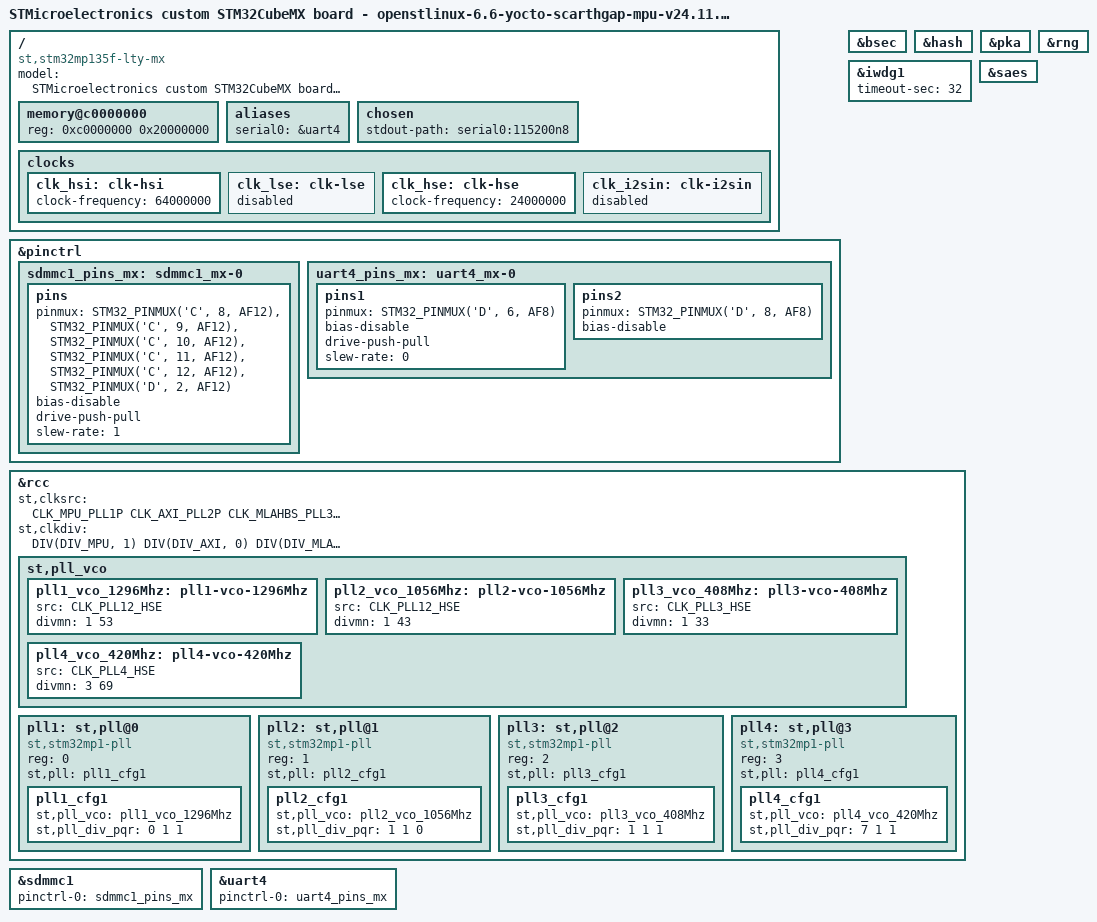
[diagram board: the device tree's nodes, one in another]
// SPDX-License-Identifier: (GPL-2.0-or-later OR BSD-3-Clause)
/*
 * Copyright (C) 2026, STMicroelectronics - All Rights Reserved
 * Author: STM32CubeMX code generation for STMicroelectronics.
 */

/* For more information on Device Tree configuration, please refer to
 * https://wiki.st.com/stm32mpu/wiki/Category:Device_tree_configuration
 */

/dts-v1/;

#include <dt-bindings/pinctrl/stm32-pinfunc.h>
#include <dt-bindings/clock/stm32mp13-clksrc.h>
#include "stm32mp13-mx.dtsi"

#include "stm32mp135.dtsi"
#include "stm32mp13xf.dtsi"
#include "stm32mp13-ddr.dtsi"

/* USER CODE BEGIN includes */
#include "stm32mp13-pinctrl.dtsi"
/* USER CODE END includes */

/ {
	model = "STMicroelectronics custom STM32CubeMX board - openstlinux-6.6-yocto-scarthgap-mpu-v24.11.06";
	compatible = "st,stm32mp135f-lty-mx", "st,stm32mp135";

	memory@c0000000 {
		device_type = "memory";
		reg = <0xc0000000 0x20000000>;

		/* USER CODE BEGIN memory */
		/* USER CODE END memory */
	};

	/* USER CODE BEGIN root */

	aliases {
		serial0 = &uart4;
	};

	chosen {
		stdout-path = "serial0:115200n8";
	}; 
	
    chosen {
        stdout-path = "serial0:115200n8";
    };	
    
  	/* USER CODE END root */

	clocks {
		/* USER CODE BEGIN clocks */
		/* USER CODE END clocks */

		clk_hsi: clk-hsi {
			clock-frequency = <64000000>;

			/* USER CODE BEGIN clk_hsi */
			/* USER CODE END clk_hsi */
		};
		clk_lse: clk-lse {
			status = "disabled";

			/* USER CODE BEGIN clk_lse */
			/* USER CODE END clk_lse */
		};
		clk_hse: clk-hse {
			clock-frequency = <24000000>;

			/* USER CODE BEGIN clk_hse */
			/* USER CODE END clk_hse */
		};
		clk_i2sin: clk-i2sin {
			status = "disabled";

			/* USER CODE BEGIN clk_i2sin */
			/* USER CODE END clk_i2sin */
		};
	};

}; /*root*/

&pinctrl {
	sdmmc1_pins_mx: sdmmc1_mx-0 {
		pins {
			pinmux = <STM32_PINMUX('C', 8, AF12)>, /* SDMMC1_D0 */
					 <STM32_PINMUX('C', 9, AF12)>, /* SDMMC1_D1 */
					 <STM32_PINMUX('C', 10, AF12)>, /* SDMMC1_D2 */
					 <STM32_PINMUX('C', 11, AF12)>, /* SDMMC1_D3 */
					 <STM32_PINMUX('C', 12, AF12)>, /* SDMMC1_CK */
					 <STM32_PINMUX('D', 2, AF12)>; /* SDMMC1_CMD */
			bias-disable;
			drive-push-pull;
			slew-rate = <1>;
		};
	};

	/* USER CODE BEGIN pinctrl */
	uart4_pins_mx: uart4_mx-0 {
		pins1 {
			pinmux = <STM32_PINMUX('D', 6, AF8)>; /* UART4_TX */
			bias-disable;
			drive-push-pull;
			slew-rate = <0>;
		};
		pins2 {
			pinmux = <STM32_PINMUX('D', 8, AF8)>; /* UART4_RX */
			bias-disable;
		};
	};	
	/* USER CODE END pinctrl */
};

&bsec {
	status = "okay";

	/* USER CODE BEGIN bsec */
	/* USER CODE END bsec */
};

&hash {
	status = "okay";

	/* USER CODE BEGIN hash */
	/* USER CODE END hash */
};

&iwdg1 {
	status = "okay";

	/* USER CODE BEGIN iwdg1 */
	timeout-sec = <32>;	
	/* USER CODE END iwdg1 */
};

&pka {
	status = "okay";

	/* USER CODE BEGIN pka */
	/* USER CODE END pka */
};

&rcc {
	status = "okay";

	/* USER CODE BEGIN rcc */
	/* USER CODE END rcc */

	st,clksrc = <
		CLK_MPU_PLL1P
		CLK_AXI_PLL2P
		CLK_MLAHBS_PLL3
		CLK_CKPER_DISABLED
		CLK_SDMMC1_PLL4P
		CLK_STGEN_HSE
		CLK_UART4_HSI
		CLK_RNG1_PLL4R
		CLK_SAES_AXI
	>;
	st,clkdiv = <
		DIV(DIV_MPU, 1)
		DIV(DIV_AXI, 0)
		DIV(DIV_MLAHB, 0)
		DIV(DIV_APB1, 1)
		DIV(DIV_APB2, 1)
		DIV(DIV_APB3, 1)
		DIV(DIV_APB4, 1)
		DIV(DIV_APB5, 2)
		DIV(DIV_APB6, 1)
	>;
	st,pll_vco {
		pll1_vco_1296Mhz: pll1-vco-1296Mhz {
			src = < CLK_PLL12_HSE >;
			divmn = < 1 53 >;
		};
		pll2_vco_1056Mhz: pll2-vco-1056Mhz {
			src = < CLK_PLL12_HSE >;
			divmn = < 1 43 >;
		};
		pll3_vco_408Mhz: pll3-vco-408Mhz {
			src = < CLK_PLL3_HSE >;
			divmn = < 1 33 >;
		};
		pll4_vco_420Mhz: pll4-vco-420Mhz {
			src = < CLK_PLL4_HSE >;
			divmn = < 3 69 >;
		};
		/* USER CODE BEGIN rcc_st-pll_vco */
		/* USER CODE END rcc_st-pll_vco */
	};

	pll1:st,pll@0 {
		compatible = "st,stm32mp1-pll";
		reg = <0>;

		st,pll = < &pll1_cfg1 >;

		pll1_cfg1: pll1_cfg1 {
			st,pll_vco = < &pll1_vco_1296Mhz >;
			st,pll_div_pqr = < 0 1 1 >;
		};
		/* USER CODE BEGIN pll1 */
		/* USER CODE END pll1 */
	};

	pll2:st,pll@1 {
		compatible = "st,stm32mp1-pll";
		reg = <1>;

		st,pll = < &pll2_cfg1 >;

		pll2_cfg1: pll2_cfg1 {
			st,pll_vco = < &pll2_vco_1056Mhz >;
			st,pll_div_pqr = < 1 1 0 >;
		};
		/* USER CODE BEGIN pll2 */
		/* USER CODE END pll2 */
	};

	pll3:st,pll@2 {
		compatible = "st,stm32mp1-pll";
		reg = <2>;

		st,pll = < &pll3_cfg1 >;

		pll3_cfg1: pll3_cfg1 {
			st,pll_vco = < &pll3_vco_408Mhz >;
			st,pll_div_pqr = < 1 1 1 >;
		};
		/* USER CODE BEGIN pll3 */
		/* USER CODE END pll3 */
	};

	pll4:st,pll@3 {
		compatible = "st,stm32mp1-pll";
		reg = <3>;

		st,pll = < &pll4_cfg1 >;

		pll4_cfg1: pll4_cfg1 {
			st,pll_vco = < &pll4_vco_420Mhz >;
			st,pll_div_pqr = < 7 1 1 >;
		};
		/* USER CODE BEGIN pll4 */
		/* USER CODE END pll4 */
	};

};

&rng {
	status = "okay";

	/* USER CODE BEGIN rng */
	/* USER CODE END rng */
};

&saes {
	status = "okay";

	/* USER CODE BEGIN saes */
	/* USER CODE END saes */
};

&sdmmc1 {
	pinctrl-names = "default";
	pinctrl-0 = <&sdmmc1_pins_mx>;
	status = "okay";

	/* USER CODE BEGIN sdmmc1 */
	/* USER CODE END sdmmc1 */
};

&uart4 {
	status = "okay";

	/* USER CODE BEGIN uart4 */
	pinctrl-names = "default";
	pinctrl-0 = <&uart4_pins_mx>;
	/* USER CODE END uart4 */
};

/* USER CODE BEGIN addons */
/* USER CODE END addons */

